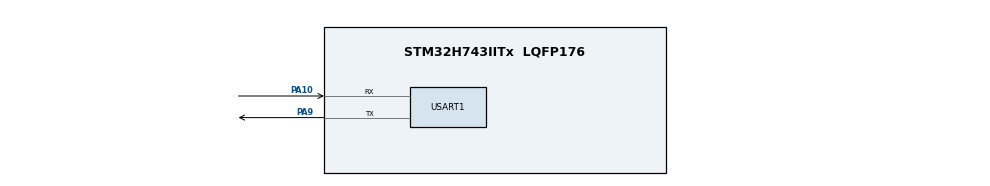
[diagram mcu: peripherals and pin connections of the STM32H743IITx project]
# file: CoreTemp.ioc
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ADC3.Channel-0\#ChannelRegularConversion=ADC_CHANNEL_TEMPSENSOR
ADC3.ClockPrescalerADC3=ADC_CLOCK_ASYNC_DIV64
ADC3.ContinuousConvMode=DISABLE
ADC3.NbrOfConversionFlag=1
ADC3.OffsetNumber-0\#ChannelRegularConversion=ADC_OFFSET_NONE
ADC3.OffsetSignedSaturation-0\#ChannelRegularConversion=DISABLE
ADC3.Overrun=ADC_OVR_DATA_PRESERVED
ADC3.Rank-0\#ChannelRegularConversion=1
ADC3.Resolution=ADC_RESOLUTION_16B
ADC3.SamplingTime-0\#ChannelRegularConversion=ADC_SAMPLETIME_810CYCLES_5
CORTEX_M7.AccessPermission_Spec=MPU_REGION_FULL_ACCESS
CORTEX_M7.BaseAddress_Spec=0xD0000000
CORTEX_M7.CPU_DCache=Enabled
CORTEX_M7.CPU_ICache=Enabled
CORTEX_M7.DisableExec_Spec=MPU_INSTRUCTION_ACCESS_ENABLE
CORTEX_M7.IsCacheable_Spec=MPU_ACCESS_CACHEABLE
CORTEX_M7.IsShareable_Spec=MPU_ACCESS_NOT_SHAREABLE
CORTEX_M7.MPU_Control=MPU_PRIVILEGED_DEFAULT
CORTEX_M7.Size_Spec=MPU_REGION_SIZE_8MB
CORTEX_M7.SubRegionDisable_Spec=0x0
CORTEX_M7.default_mode_Activation=1
Mcu.Family=STM32H7
Mcu.Name=STM32H743IITx
Mcu.Package=LQFP176
NVIC.PriorityGroup=NVIC_PRIORITYGROUP_4
NVIC.TIM1_UP_IRQn=true\:15\:0\:false\:false\:true\:false\:true\:true
NVIC.TimeBase=TIM1_UP_IRQn
NVIC.TimeBaseIP=TIM1
PA10.Mode=Asynchronous
PA10.Signal=USART1_RX
PA13\ (JTMS/SWDIO).Mode=Serial_Wire
PA13\ (JTMS/SWDIO).Signal=DEBUG_JTMS-SWDIO
PA14\ (JTCK/SWCLK).Mode=Serial_Wire
PA14\ (JTCK/SWCLK).Signal=DEBUG_JTCK-SWCLK
PA9.Mode=Asynchronous
PA9.Signal=USART1_TX
PH0-OSC_IN\ (PH0).Mode=HSE-External-Oscillator
PH0-OSC_IN\ (PH0).Signal=RCC_OSC_IN
PH1-OSC_OUT\ (PH1).Mode=HSE-External-Oscillator
PH1-OSC_OUT\ (PH1).Signal=RCC_OSC_OUT
ProjectManager.HeapSize=0x200
ProjectManager.StackSize=0x400
ProjectManager.TargetToolchain=STM32CubeIDE
RCC.ADCFreq_Value=75000000
RCC.APB1Freq_Value=37500000
RCC.APB2Freq_Value=37500000
RCC.APB3Freq_Value=37500000
RCC.APB4Freq_Value=75000000
RCC.CortexFreq_Value=75000000
RCC.D1PPRE=RCC_APB3_DIV2
RCC.D2PPRE1=RCC_APB1_DIV2
RCC.D2PPRE2=RCC_APB2_DIV2
RCC.DIVM1=4
RCC.DIVM2=4
RCC.DIVM3=1
RCC.DIVN1=9
RCC.DIVN2=9
RCC.DIVN3=4
RCC.DIVR3=6
RCC.HCLKFreq_Value=75000000
RCC.HSE_VALUE=8000000
RCC.PLL2FRACN=3072
RCC.PLL3FRACN=0
RCC.PLLFRACN=3072
RCC.SYSCLKFreq_VALUE=75000000
RCC.SYSCLKSource=RCC_SYSCLKSOURCE_PLLCLK
RCC.USBFreq_Value=75000000
USART1.VirtualMode-Asynchronous=VM_ASYNC
VP_ADC3_TempSens_Input.Mode=IN-TempSens
VP_SYS_VS_tim1.Mode=TIM1
board=custom

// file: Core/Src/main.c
/* USER CODE BEGIN Header */
/**
  ******************************************************************************
  * @file           : main.c
  * @brief          : Main program body
  ******************************************************************************
  * @attention
  *
  * Copyright (c) 2024 STMicroelectronics.
  * All rights reserved.
  *
  * This software is licensed under terms that can be found in the LICENSE file
  * in the root directory of this software component.
  * If no LICENSE file comes with this software, it is provided AS-IS.
  *
  ******************************************************************************
  */
/* USER CODE END Header */
#include "main.h"

/* USER CODE BEGIN Includes */
#include "string.h"
#include "stdio.h"
#include "stdarg.h"
#include "stdlib.h"
/* USER CODE END Includes */

/* USER CODE BEGIN PD */
#define TS_CAL1_REG 0x1FF1E820
#define TS_CAL2_REG 0x1FF1E840
/* USER CODE END PD */

ADC_HandleTypeDef hadc3;

UART_HandleTypeDef huart1;

/* USER CODE BEGIN PV */
uint32_t adc_val;
/* USER CODE END PV */

void SystemClock_Config(void);
static void MPU_Config(void);
static void MX_GPIO_Init(void);
static void MX_USART1_UART_Init(void);
static void MX_ADC3_Init(void);

/* USER CODE BEGIN 0 */
void UART_Printf(const char* fmt, ...)
{
    char buff[256];
    va_list args;
    va_start(args, fmt);
    vsnprintf(buff, sizeof(buff), fmt, args);
    HAL_UART_Transmit(&huart1, (uint8_t*)buff, strlen(buff), HAL_MAX_DELAY);
    va_end(args);
}

float MCU_TemperatureCalculate(uint32_t ts_data)
{
	float temperature_cal1 = 30.0;
	float temperature_cal2 = 110.0;
    uint16_t *ts_cal1 = (uint16_t *)0x1FF1E820; // TS_CAL1 @ VREF+ = 3.3 V, at 30 °C
	uint16_t *ts_cal2 = (uint16_t *)0x1FF1E840; // TS_CAL2 @ VREF+ = 3.3 V, at 110 °C
	return (((float)ts_data - (float)(*ts_cal1)) * (temperature_cal2 - temperature_cal1)) / ((float)(*ts_cal2) - (float)(*ts_cal1)) + temperature_cal1;
}
/* USER CODE END 0 */

int main(void)
{

  /* MPU Configuration--------------------------------------------------------*/
  MPU_Config();
/* Enable the CPU Cache */

  /* Enable I-Cache---------------------------------------------------------*/
  SCB_EnableICache();

  /* Enable D-Cache---------------------------------------------------------*/
  SCB_EnableDCache();

  /* MCU Configuration--------------------------------------------------------*/

  /* Reset of all peripherals, Initializes the Flash interface and the Systick. */
  HAL_Init();

  /* Configure the system clock */
  SystemClock_Config();

  /* Initialize all configured peripherals */
  MX_GPIO_Init();
  MX_USART1_UART_Init();
  MX_ADC3_Init();
  /* USER CODE BEGIN 2 */
  HAL_ADCEx_Calibration_Start(&hadc3, ADC_CALIB_OFFSET, ADC_SINGLE_ENDED);
  /* USER CODE END 2 */

  /* Infinite loop */
  while (1)
  {

    /* USER CODE BEGIN 3 */
	  HAL_ADC_Start(&hadc3); // start the adc
	  if (HAL_ADC_PollForConversion(&hadc3, 100) == HAL_OK)
		  UART_Printf("Temp: %f\r\n", MCU_TemperatureCalculate(HAL_ADC_GetValue(&hadc3)));
	  else
		  UART_Printf("ADC conversion not finished!\r\n");
	  HAL_Delay(500);
  }
  /* USER CODE END 3 */
}

void SystemClock_Config(void)
{
  RCC_OscInitTypeDef RCC_OscInitStruct = {0};
  RCC_ClkInitTypeDef RCC_ClkInitStruct = {0};

  /** Supply configuration update enable
  */
  HAL_PWREx_ConfigSupply(PWR_LDO_SUPPLY);

  /** Configure the main internal regulator output voltage
  */
  __HAL_PWR_VOLTAGESCALING_CONFIG(PWR_REGULATOR_VOLTAGE_SCALE3);

  while(!__HAL_PWR_GET_FLAG(PWR_FLAG_VOSRDY)) {}

  /** Initializes the RCC Oscillators according to the specified parameters
  * in the RCC_OscInitTypeDef structure.
  */
  RCC_OscInitStruct.OscillatorType = RCC_OSCILLATORTYPE_HSI;
  RCC_OscInitStruct.HSIState = RCC_HSI_DIV1;
  RCC_OscInitStruct.HSICalibrationValue = RCC_HSICALIBRATION_DEFAULT;
  RCC_OscInitStruct.PLL.PLLState = RCC_PLL_ON;
  RCC_OscInitStruct.PLL.PLLSource = RCC_PLLSOURCE_HSI;
  RCC_OscInitStruct.PLL.PLLM = 4;
  RCC_OscInitStruct.PLL.PLLN = 9;
  RCC_OscInitStruct.PLL.PLLP = 2;
  RCC_OscInitStruct.PLL.PLLQ = 2;
  RCC_OscInitStruct.PLL.PLLR = 2;
  RCC_OscInitStruct.PLL.PLLRGE = RCC_PLL1VCIRANGE_3;
  RCC_OscInitStruct.PLL.PLLVCOSEL = RCC_PLL1VCOMEDIUM;
  RCC_OscInitStruct.PLL.PLLFRACN = 3072;
  if (HAL_RCC_OscConfig(&RCC_OscInitStruct) != HAL_OK)
  {
    Error_Handler();
  }

  /** Initializes the CPU, AHB and APB buses clocks
  */
  RCC_ClkInitStruct.ClockType = RCC_CLOCKTYPE_HCLK|RCC_CLOCKTYPE_SYSCLK
                              |RCC_CLOCKTYPE_PCLK1|RCC_CLOCKTYPE_PCLK2
                              |RCC_CLOCKTYPE_D3PCLK1|RCC_CLOCKTYPE_D1PCLK1;
  RCC_ClkInitStruct.SYSCLKSource = RCC_SYSCLKSOURCE_PLLCLK;
  RCC_ClkInitStruct.SYSCLKDivider = RCC_SYSCLK_DIV1;
  RCC_ClkInitStruct.AHBCLKDivider = RCC_HCLK_DIV1;
  RCC_ClkInitStruct.APB3CLKDivider = RCC_APB3_DIV2;
  RCC_ClkInitStruct.APB1CLKDivider = RCC_APB1_DIV2;
  RCC_ClkInitStruct.APB2CLKDivider = RCC_APB2_DIV2;
  RCC_ClkInitStruct.APB4CLKDivider = RCC_APB4_DIV1;

  if (HAL_RCC_ClockConfig(&RCC_ClkInitStruct, FLASH_LATENCY_1) != HAL_OK)
  {
    Error_Handler();
  }
}

static void MX_ADC3_Init(void)
{

  ADC_ChannelConfTypeDef sConfig = {0};

  /** Common config
  */
  hadc3.Instance = ADC3;
  hadc3.Init.Resolution = ADC_RESOLUTION_16B;
  hadc3.Init.ScanConvMode = ADC_SCAN_DISABLE;
  hadc3.Init.EOCSelection = ADC_EOC_SINGLE_CONV;
  hadc3.Init.LowPowerAutoWait = DISABLE;
  hadc3.Init.ContinuousConvMode = DISABLE;
  hadc3.Init.NbrOfConversion = 1;
  hadc3.Init.DiscontinuousConvMode = DISABLE;
  hadc3.Init.ExternalTrigConv = ADC_SOFTWARE_START;
  hadc3.Init.ExternalTrigConvEdge = ADC_EXTERNALTRIGCONVEDGE_NONE;
  hadc3.Init.ConversionDataManagement = ADC_CONVERSIONDATA_DR;
  hadc3.Init.Overrun = ADC_OVR_DATA_PRESERVED;
  hadc3.Init.LeftBitShift = ADC_LEFTBITSHIFT_NONE;
  hadc3.Init.OversamplingMode = DISABLE;
  if (HAL_ADC_Init(&hadc3) != HAL_OK)
  {
    Error_Handler();
  }

  /** Configure Regular Channel
  */
  sConfig.Channel = ADC_CHANNEL_TEMPSENSOR;
  sConfig.Rank = ADC_REGULAR_RANK_1;
  sConfig.SamplingTime = ADC_SAMPLETIME_810CYCLES_5;
  sConfig.SingleDiff = ADC_SINGLE_ENDED;
  sConfig.OffsetNumber = ADC_OFFSET_NONE;
  sConfig.Offset = 0;
  sConfig.OffsetSignedSaturation = DISABLE;
  if (HAL_ADC_ConfigChannel(&hadc3, &sConfig) != HAL_OK)
  {
    Error_Handler();
  }

}

static void MX_USART1_UART_Init(void)
{

  huart1.Instance = USART1;
  huart1.Init.BaudRate = 115200;
  huart1.Init.WordLength = UART_WORDLENGTH_8B;
  huart1.Init.StopBits = UART_STOPBITS_1;
  huart1.Init.Parity = UART_PARITY_NONE;
  huart1.Init.Mode = UART_MODE_TX_RX;
  huart1.Init.HwFlowCtl = UART_HWCONTROL_NONE;
  huart1.Init.OverSampling = UART_OVERSAMPLING_16;
  huart1.Init.OneBitSampling = UART_ONE_BIT_SAMPLE_DISABLE;
  huart1.Init.ClockPrescaler = UART_PRESCALER_DIV1;
  huart1.AdvancedInit.AdvFeatureInit = UART_ADVFEATURE_NO_INIT;
  if (HAL_UART_Init(&huart1) != HAL_OK)
  {
    Error_Handler();
  }
  if (HAL_UARTEx_SetTxFifoThreshold(&huart1, UART_TXFIFO_THRESHOLD_1_8) != HAL_OK)
  {
    Error_Handler();
  }
  if (HAL_UARTEx_SetRxFifoThreshold(&huart1, UART_RXFIFO_THRESHOLD_1_8) != HAL_OK)
  {
    Error_Handler();
  }
  if (HAL_UARTEx_DisableFifoMode(&huart1) != HAL_OK)
  {
    Error_Handler();
  }

}

static void MX_GPIO_Init(void)
{

  /* GPIO Ports Clock Enable */
  __HAL_RCC_GPIOH_CLK_ENABLE();
  __HAL_RCC_GPIOA_CLK_ENABLE();

}

/* MPU Configuration */

void MPU_Config(void)
{
  MPU_Region_InitTypeDef MPU_InitStruct = {0};

  /* Disables the MPU */
  HAL_MPU_Disable();

  /** Initializes and configures the Region and the memory to be protected
  */
  MPU_InitStruct.Enable = MPU_REGION_ENABLE;
  MPU_InitStruct.Number = MPU_REGION_NUMBER0;
  MPU_InitStruct.BaseAddress = 0xD0000000;
  MPU_InitStruct.Size = MPU_REGION_SIZE_8MB;
  MPU_InitStruct.SubRegionDisable = 0x0;
  MPU_InitStruct.TypeExtField = MPU_TEX_LEVEL0;
  MPU_InitStruct.AccessPermission = MPU_REGION_FULL_ACCESS;
  MPU_InitStruct.DisableExec = MPU_INSTRUCTION_ACCESS_ENABLE;
  MPU_InitStruct.IsShareable = MPU_ACCESS_NOT_SHAREABLE;
  MPU_InitStruct.IsCacheable = MPU_ACCESS_CACHEABLE;
  MPU_InitStruct.IsBufferable = MPU_ACCESS_NOT_BUFFERABLE;

  HAL_MPU_ConfigRegion(&MPU_InitStruct);
  /* Enables the MPU */
  HAL_MPU_Enable(MPU_PRIVILEGED_DEFAULT);

}

void HAL_TIM_PeriodElapsedCallback(TIM_HandleTypeDef *htim)
{
  if (htim->Instance == TIM1) {
    HAL_IncTick();
  }
}

void Error_Handler(void)
{
  __disable_irq();
  while (1)
  {
  }
}
